# STM32L053 register map
File version: 1.2
CPU: CM0+ r0p0, little endian, MPU, no FPU, 4 interrupt priority bits
Registers are 32-bit, read-write, reset 0x0 unless marked. A register's access mark holds for its fields unless they carry their own. Offsets are from the block's base; [hi:lo] are bit positions; {n}, {i} and the like mark numbered series.

## IWDG — Independent watchdog
Base 0x40003000
0x00 KR wo — Key register
  [15:0] KEY — Key value (write only, read 0x0000)
0x04 PR — Prescaler register
  [2:0] PR — Prescaler divider
0x08 RLR reset 0xFFF — Reload register
  [11:0] RL — Watchdog counter reload value
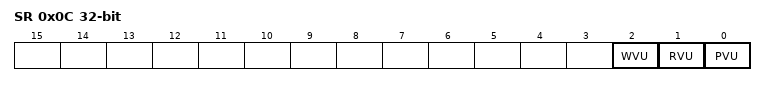
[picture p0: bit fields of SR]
0x0C SR ro — Status register
  [2] WVU — Watchdog counter window value update
  [1] RVU — Watchdog counter reload value update
  [0] PVU — Watchdog prescaler value update
0x10 WINR reset 0xFFF — Window register
  [11:0] WIN — Watchdog counter window value

## WWDG — System window watchdog
Base 0x40002C00
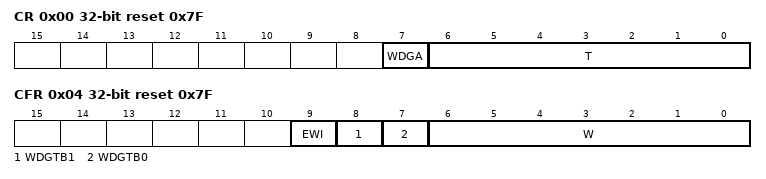
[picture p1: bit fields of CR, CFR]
0x00 CR reset 0x7F — Control register
  [7] WDGA — Activation bit
  [6:0] T — 7-bit counter (MSB to LSB)
0x04 CFR reset 0x7F — Configuration register
  [9] EWI — Early wakeup interrupt
  [8] WDGTB1 — Timer base
  [7] WDGTB0
  [6:0] W — 7-bit window value
0x08 SR — Status register
  [0] EWIF — Early wakeup interrupt flag

## USB_FS — Universal serial bus full-speed device interface
Base 0x40005C00
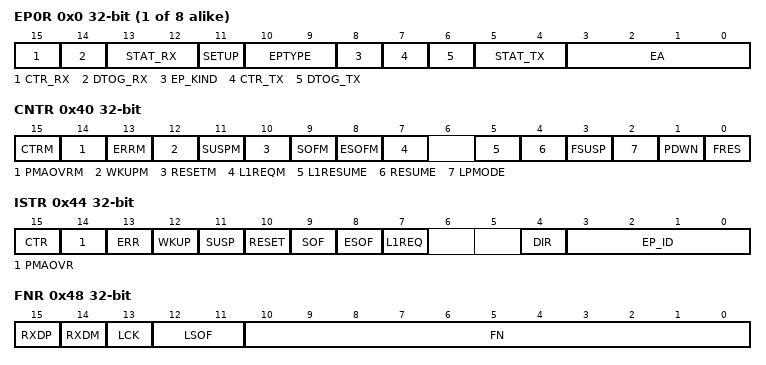
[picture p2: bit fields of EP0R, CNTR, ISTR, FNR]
{0x0+4i} EP{i}R (i=0..7) — endpoint register
  [15] CTR_RX, [14] DTOG_RX, [13:12] STAT_RX, [11] SETUP, [10:9] EPTYPE, [8] EP_KIND, [7] CTR_TX, [6] DTOG_TX, [5:4] STAT_TX, [3:0] EA
0x40 CNTR — control register
  [15] CTRM, [14] PMAOVRM, [13] ERRM, [12] WKUPM, [11] SUSPM, [10] RESETM, [9] SOFM, [8] ESOFM, [7] L1REQM, [5] L1RESUME, [4] RESUME, [3] FSUSP, [2] LPMODE, [1] PDWN, [0] FRES
0x44 ISTR — interrupt status register
  [15] CTR, [14] PMAOVR, [13] ERR, [12] WKUP, [11] SUSP, [10] RESET, [9] SOF, [8] ESOF, [7] L1REQ, [4] DIR, [3:0] EP_ID
0x48 FNR ro — frame number register
  [15] RXDP, [14] RXDM, [13] LCK, [12:11] LSOF, [10:0] FN
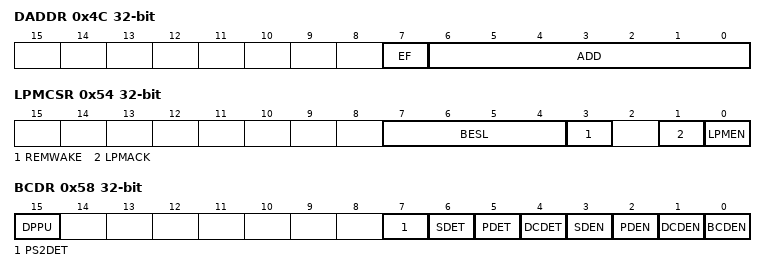
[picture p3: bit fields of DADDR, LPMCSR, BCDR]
0x4C DADDR — device address
  [7] EF, [6:0] ADD
0x50 BTABLE — Buffer table address
  [15:3] BTABLE
0x54 LPMCSR access per field — LPM control and status register
  [7:4] BESL ro, [3] REMWAKE ro, [1] LPMACK rw, [0] LPMEN rw
0x58 BCDR access per field — Battery charging detector
  [15] DPPU rw, [7] PS2DET ro, [6] SDET ro, [5] PDET ro, [4] DCDET ro, [3] SDEN rw, [2] PDEN rw, [1] DCDEN rw, [0] BCDEN rw

## CRS — Clock recovery system
Base 0x40006C00
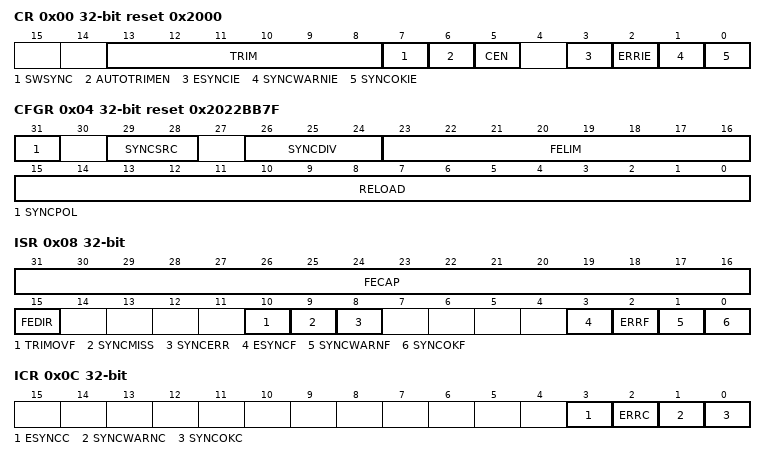
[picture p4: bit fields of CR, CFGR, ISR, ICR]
0x00 CR reset 0x2000 — control register
  [13:8] TRIM — HSI48 oscillator smooth trimming
  [7] SWSYNC — Generate software SYNC event
  [6] AUTOTRIMEN — Automatic trimming enable
  [5] CEN — Frequency error counter enable
  [3] ESYNCIE — Expected SYNC interrupt enable
  [2] ERRIE — Synchronization or trimming error interrupt enable
  [1] SYNCWARNIE — SYNC warning interrupt enable
  [0] SYNCOKIE — SYNC event OK interrupt enable
0x04 CFGR reset 0x2022BB7F — configuration register
  [31] SYNCPOL — SYNC polarity selection
  [29:28] SYNCSRC — SYNC signal source selection
  [26:24] SYNCDIV — SYNC divider
  [23:16] FELIM — Frequency error limit
  [15:0] RELOAD — Counter reload value
0x08 ISR ro — interrupt and status register
  [31:16] FECAP — Frequency error capture
  [15] FEDIR — Frequency error direction
  [10] TRIMOVF — Trimming overflow or underflow
  [9] SYNCMISS — SYNC missed
  [8] SYNCERR — SYNC error
  [3] ESYNCF — Expected SYNC flag
  [2] ERRF — Error flag
  [1] SYNCWARNF — SYNC warning flag
  [0] SYNCOKF — SYNC event OK flag
0x0C ICR — interrupt flag clear register
  [3] ESYNCC — Expected SYNC clear flag
  [2] ERRC — Error clear flag
  [1] SYNCWARNC — SYNC warning clear flag
  [0] SYNCOKC — SYNC event OK clear flag

## Firewall
Base 0x40011C00
0x00 FIREWALL_CSSA — Code segment start address
  [23:8] ADD — code segment start address
0x04 FIREWALL_CSL — Code segment length
  [21:8] LENG — code segment length
0x08 FIREWALL_NVDSSA — Non-volatile data segment start address
  [23:8] ADD
0x0C FIREWALL_NVDSL — Non-volatile data segment length
  [21:8] LENG
0x10 FIREWALL_VDSSA — Volatile data segment start address
  [15:6] ADD
0x14 FIREWALL_VDSL — Volatile data segment length
  [15:6] LENG — Non-volatile data segment length
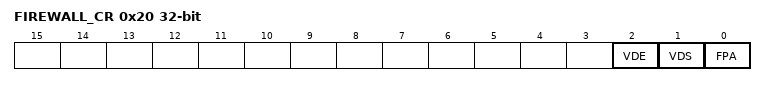
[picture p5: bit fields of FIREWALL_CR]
0x20 FIREWALL_CR — Configuration register
  [2] VDE — Volatile data execution
  [1] VDS — Volatile data shared
  [0] FPA — Firewall pre alarm

## Notices in the file
Copyright (c) 2024 STMicroelectronics.
SPDX-License-Identifier: Apache-2.0
Licensed under the Apache License, Version 2.0 (the "License");
you may not use this file except in compliance with the License.
You may obtain a copy of the License at
http://www.apache.org/licenses/LICENSE-2.0
Unless required by applicable law or agreed to in writing, software
distributed under the License is distributed on an "AS IS" BASIS,
WITHOUT WARRANTIES OR CONDITIONS OF ANY KIND, either express or implied.
See the License for the specific language governing permissions and
limitations under the License.
